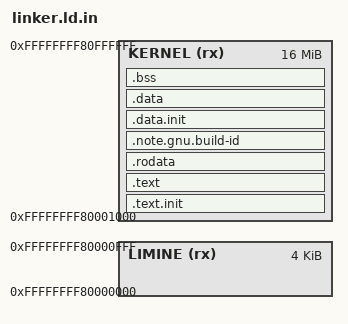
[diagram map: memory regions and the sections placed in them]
OUTPUT_FORMAT(@TARGET_OUTPUT_FORMAT@)
ENTRY(kboot)

/* Memory layout */
MEMORY
{
    LIMINE (rx) : ORIGIN = 0xFFFFFFFF80000000, LENGTH = 4K
    KERNEL (rx) : ORIGIN = 0xFFFFFFFF80001000, LENGTH = 16M-4K
}

/* Protocol preamble for bootloader */
@PROTOCOL_PREAMBLE@

SECTIONS
{
    /* Set start of kernel */
    . = @LOAD_ADDRESS@;
    __kernelStart = .;

@PROTOCOL_EARLY_SECTIONS@

    /* .text.init section */
    .text.init : {
        __textInitSectionStart = .;
        KEEP(*(.text.init))
        __textInitSectionEnd = .;
    } > KERNEL

    . = ALIGN(CONSTANT(MAXPAGESIZE));

    /* Main .text section */
    .text : {
        __textSectionStart = .;
        KEEP(*(.text))
        KEEP(*(.isr))
        KEEP(*(.irq))
        __textSectionEnd = .;
        PROVIDE(__textSectionEnd = __textSectionEnd);
    } > KERNEL

@PROTOCOL_TEXT_SECTIONS@

    . = ALIGN(CONSTANT(MAXPAGESIZE));

    /* .rodata section */
    .rodata : {
        __rodataSectionStart = .;
        *(.rodata*)
        __rodataSectionEnd = .;
    } > KERNEL

    .note.gnu.build-id : {
        *(.note.gnu.build-id)
    } > KERNEL

@PROTOCOL_RODATA_SECTIONS@

    . = ALIGN(CONSTANT(MAXPAGESIZE));

    /* Initialized .data */
    .data.init : {
        __dataInitSectionStart = .;
        *(.data.init)
        __dataInitSectionEnd = .;
    } > KERNEL

    . = ALIGN(CONSTANT(MAXPAGESIZE));

    /* Main .data section */
    .data : {
        __dataSectionStart = .;
        *(.data*)
        __dataSectionEnd = .;
    } > KERNEL

@PROTOCOL_DATA_SECTIONS@

    /* .bss section */
    .bss : {
        *(.bss*)
        *(COMMON)
    } > KERNEL

@PROTOCOL_FINAL_SECTIONS@

    /* Discard unwanted sections */
    /DISCARD/ : {
        *(.eh_frame*)
        *(.note .note.*)
    }

    /* End of kernel */
    __kernelEnd = .;
}
